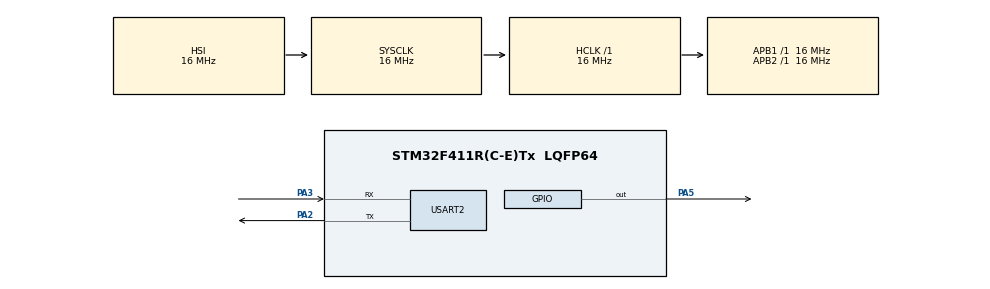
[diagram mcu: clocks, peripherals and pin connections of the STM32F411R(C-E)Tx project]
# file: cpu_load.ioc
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FREERTOS.Tasks01=blink01,0,128,StartBlink01,Default,NULL,Dynamic,NULL,NULL
FREERTOS.configGENERATE_RUN_TIME_STATS=1
FREERTOS.configUSE_NEWLIB_REENTRANT=1
FREERTOS.configUSE_STATS_FORMATTING_FUNCTIONS=1
FREERTOS.configUSE_TRACE_FACILITY=1
Mcu.Family=STM32F4
Mcu.Name=STM32F411R(C-E)Tx
Mcu.Package=LQFP64
NVIC.PriorityGroup=NVIC_PRIORITYGROUP_4
NVIC.TIM1_UP_TIM10_IRQn=true\:5\:0\:false\:false\:true\:true\:true\:true\:true
NVIC.TIM3_IRQn=true\:15\:0\:false\:false\:true\:false\:false\:true\:true
NVIC.TimeBase=TIM3_IRQn
NVIC.TimeBaseIP=TIM3
PA13.Mode=Trace_Asynchronous_SW
PA13.Signal=SYS_JTMS-SWDIO
PA14.Mode=Trace_Asynchronous_SW
PA14.Signal=SYS_JTCK-SWCLK
PA2.Mode=Asynchronous
PA2.Signal=USART2_TX
PA3.Mode=Asynchronous
PA3.Signal=USART2_RX
PA5.Signal=GPIO_Output
PB3.Mode=Trace_Asynchronous_SW
PB3.Signal=SYS_JTDO-SWO
ProjectManager.HeapSize=0x200
ProjectManager.StackSize=0x400
ProjectManager.TargetToolchain=STM32CubeIDE
RCC.AHBFreq_Value=16000000
RCC.APB1Freq_Value=16000000
RCC.APB2Freq_Value=16000000
RCC.CortexFreq_Value=16000000
RCC.HSE_VALUE=25000000
RCC.HSI_VALUE=16000000
RCC.LSE_VALUE=32768
RCC.SYSCLKFreq_VALUE=16000000
RCC.VCOOutputFreq_Value=192000000
TIM10.Period=4199
USART2.VirtualMode=VM_ASYNC
VP_FREERTOS_VS_CMSIS_V1.Mode=CMSIS_V1
VP_SYS_VS_tim3.Mode=TIM3
VP_TIM10_VS_ClockSourceINT.Mode=Enable_Timer
board=custom

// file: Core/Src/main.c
/* USER CODE BEGIN Header */
/**
  ******************************************************************************
  * @file           : main.c
  * @brief          : Main program body
  ******************************************************************************
  * @attention
  *
  * Copyright (c) 2024 STMicroelectronics.
  * All rights reserved.
  *
  * This software is licensed under terms that can be found in the LICENSE file
  * in the root directory of this software component.
  * If no LICENSE file comes with this software, it is provided AS-IS.
  *
  ******************************************************************************
  */
/* USER CODE END Header */
#include "main.h"
#include "cmsis_os.h"

TIM_HandleTypeDef htim10;

UART_HandleTypeDef huart2;

osThreadId blink01Handle;

void SystemClock_Config(void);
static void MX_GPIO_Init(void);
static void MX_TIM10_Init(void);
static void MX_USART2_UART_Init(void);
void StartBlink01(void const * argument);

/* USER CODE BEGIN PFP */

#ifdef __GNUC__
#define PUTCHAR_PROTOTYPE int __io_putchar(int ch)
#else
#define PUTCHAR_PROTOTYPE int fputc(int ch, FILE *f)
#endif

PUTCHAR_PROTOTYPE
{
  HAL_UART_Transmit(&huart2, (uint8_t *)&ch, 1, HAL_MAX_DELAY);
  return ch;
}

/* USER CODE END PFP */

int main(void)
{

  /* MCU Configuration--------------------------------------------------------*/

  /* Reset of all peripherals, Initializes the Flash interface and the Systick. */
  HAL_Init();

  /* Configure the system clock */
  SystemClock_Config();

  /* Initialize all configured peripherals */
  MX_GPIO_Init();
  MX_TIM10_Init();
  MX_USART2_UART_Init();
  /* USER CODE BEGIN 2 */

  HAL_TIM_Base_Start(&htim10);

  /* USER CODE END 2 */

  /* Create the thread(s) */
  /* definition and creation of blink01 */
  osThreadDef(blink01, StartBlink01, osPriorityNormal, 0, 128);
  blink01Handle = osThreadCreate(osThread(blink01), NULL);

  /* Start scheduler */
  osKernelStart();

  /* We should never get here as control is now taken by the scheduler */

  /* Infinite loop */
  while (1)
  {

  }
}

void SystemClock_Config(void)
{
  RCC_OscInitTypeDef RCC_OscInitStruct = {0};
  RCC_ClkInitTypeDef RCC_ClkInitStruct = {0};

  /** Configure the main internal regulator output voltage
  */
  __HAL_RCC_PWR_CLK_ENABLE();
  __HAL_PWR_VOLTAGESCALING_CONFIG(PWR_REGULATOR_VOLTAGE_SCALE1);

  /** Initializes the RCC Oscillators according to the specified parameters
  * in the RCC_OscInitTypeDef structure.
  */
  RCC_OscInitStruct.OscillatorType = RCC_OSCILLATORTYPE_HSI;
  RCC_OscInitStruct.HSIState = RCC_HSI_ON;
  RCC_OscInitStruct.HSICalibrationValue = RCC_HSICALIBRATION_DEFAULT;
  RCC_OscInitStruct.PLL.PLLState = RCC_PLL_NONE;
  if (HAL_RCC_OscConfig(&RCC_OscInitStruct) != HAL_OK)
  {
    Error_Handler();
  }

  /** Initializes the CPU, AHB and APB buses clocks
  */
  RCC_ClkInitStruct.ClockType = RCC_CLOCKTYPE_HCLK|RCC_CLOCKTYPE_SYSCLK
                              |RCC_CLOCKTYPE_PCLK1|RCC_CLOCKTYPE_PCLK2;
  RCC_ClkInitStruct.SYSCLKSource = RCC_SYSCLKSOURCE_HSI;
  RCC_ClkInitStruct.AHBCLKDivider = RCC_SYSCLK_DIV1;
  RCC_ClkInitStruct.APB1CLKDivider = RCC_HCLK_DIV1;
  RCC_ClkInitStruct.APB2CLKDivider = RCC_HCLK_DIV1;

  if (HAL_RCC_ClockConfig(&RCC_ClkInitStruct, FLASH_LATENCY_0) != HAL_OK)
  {
    Error_Handler();
  }
}

static void MX_TIM10_Init(void)
{

  htim10.Instance = TIM10;
  htim10.Init.Prescaler = 0;
  htim10.Init.CounterMode = TIM_COUNTERMODE_UP;
  htim10.Init.Period = 4199;
  htim10.Init.ClockDivision = TIM_CLOCKDIVISION_DIV1;
  htim10.Init.AutoReloadPreload = TIM_AUTORELOAD_PRELOAD_DISABLE;
  if (HAL_TIM_Base_Init(&htim10) != HAL_OK)
  {
    Error_Handler();
  }

}

static void MX_USART2_UART_Init(void)
{

  huart2.Instance = USART2;
  huart2.Init.BaudRate = 115200;
  huart2.Init.WordLength = UART_WORDLENGTH_8B;
  huart2.Init.StopBits = UART_STOPBITS_1;
  huart2.Init.Parity = UART_PARITY_NONE;
  huart2.Init.Mode = UART_MODE_TX_RX;
  huart2.Init.HwFlowCtl = UART_HWCONTROL_NONE;
  huart2.Init.OverSampling = UART_OVERSAMPLING_16;
  if (HAL_UART_Init(&huart2) != HAL_OK)
  {
    Error_Handler();
  }

}

static void MX_GPIO_Init(void)
{
  GPIO_InitTypeDef GPIO_InitStruct = {0};

  /* GPIO Ports Clock Enable */
  __HAL_RCC_GPIOA_CLK_ENABLE();
  __HAL_RCC_GPIOB_CLK_ENABLE();

  /*Configure GPIO pin Output Level */
  HAL_GPIO_WritePin(GPIOA, GPIO_PIN_5, GPIO_PIN_RESET);

  /*Configure GPIO pin : PA5 */
  GPIO_InitStruct.Pin = GPIO_PIN_5;
  GPIO_InitStruct.Mode = GPIO_MODE_OUTPUT_PP;
  GPIO_InitStruct.Pull = GPIO_NOPULL;
  GPIO_InitStruct.Speed = GPIO_SPEED_FREQ_LOW;
  HAL_GPIO_Init(GPIOA, &GPIO_InitStruct);

}

void StartBlink01(void const * argument)
{
  /* USER CODE BEGIN 5 */

  // TaskStatus_t structure to hold the task information
  TaskStatus_t xTaskDetails;

  // Retrieve task information for the current task (blink01)
//  vTaskGetInfo(NULL, &xTaskDetails, pdTRUE, eInvalid);
//
//  // Print task information
//  printf("Task Name: %s\n\r", xTaskDetails.pcTaskName);
//  printf("Task Handle: %p\n\r", xTaskDetails.xHandle);
//  printf("Task Priority: %u\n\r", (unsigned int)xTaskDetails.uxCurrentPriority);
//  printf("Task Stack High Water Mark: %u\n\r", (unsigned int)xTaskDetails.usStackHighWaterMark);
//  printf("Task State: ");

//  switch (xTaskDetails.eCurrentState)
//  {
//    case eReady:
//        printf("Ready\n");
//        break;
//    case eRunning:
//        printf("Running\n");
//        break;
//    case eBlocked:
//        printf("Blocked\n");
//        break;
//    case eSuspended:
//        printf("Suspended\n");
//        break;
//    case eDeleted:
//        printf("Deleted\n");
//        break;
//    default:
//        printf("Unknown\n");
//        break;
//  }

  /* Infinite loop */
  for(;;)
  {
    HAL_GPIO_TogglePin(GPIOA, GPIO_PIN_5);
    osDelay(1000);  // Delay to slow down toggling for easier observation
    vTaskGetInfo(NULL, &xTaskDetails, pdTRUE, eInvalid);
    printf("Task Run Time: %lu\n\r", xTaskDetails.ulRunTimeCounter);
  }
  /* USER CODE END 5 */
}

void HAL_TIM_PeriodElapsedCallback(TIM_HandleTypeDef *htim)
{
  if (htim->Instance == TIM3) {
    HAL_IncTick();
  }
}

void Error_Handler(void)
{
  __disable_irq();
  while (1)
  {
  }
}
